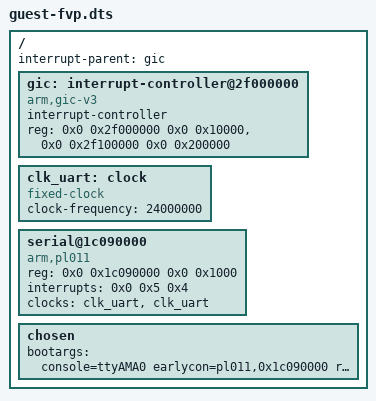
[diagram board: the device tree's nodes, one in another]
/**
 * @file bsp/fvp/dts/guest-fvp.dts
 * @brief Guest device tree for the Arm FVP_Base_RevC-2xAEMvA model.
 * @ingroup bsp
 */

/dts-v1/;
/include/ "guest-base.dtsi"

/ {
	interrupt-parent = <&gic>;

	gic: interrupt-controller@2f000000 {
		compatible = "arm,gic-v3";
		#interrupt-cells = <3>;
		#address-cells = <0>;
		interrupt-controller;
		reg = <0x0 0x2f000000 0x0 0x10000>,
		      <0x0 0x2f100000 0x0 0x200000>;
	};

	clk_uart: clock {
		compatible = "fixed-clock";
		#clock-cells = <0>;
		clock-frequency = <24000000>;
	};

	serial@1c090000 {
		compatible = "arm,pl011", "arm,primecell";
		reg = <0x0 0x1c090000 0x0 0x1000>;
		interrupts = <0x0 0x5 0x4>;
		clocks = <&clk_uart &clk_uart>;
		clock-names = "uartclk", "apb_pclk";
	};

	chosen {
		bootargs = "console=ttyAMA0 earlycon=pl011,0x1c090000 root=/dev/ram0 rdinit=/sbin/init";
	};
};
